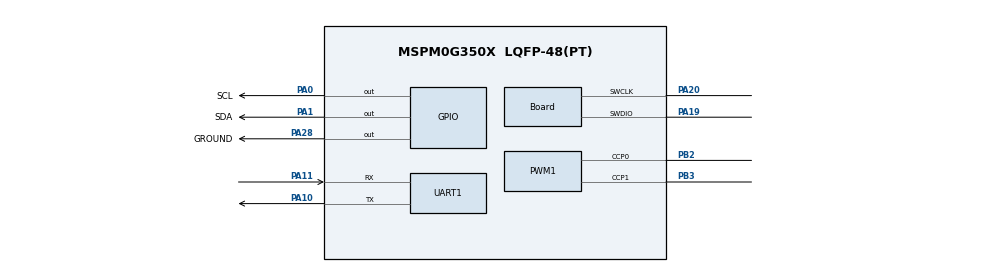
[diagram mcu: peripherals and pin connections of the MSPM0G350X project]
/**
 * These arguments were used when this file was generated. They will be automatically applied on subsequent loads
 * via the GUI or CLI. Run CLI with '--help' for additional information on how to override these arguments.
 * @cliArgs --device "MSPM0G350X" --package "LQFP-48(PT)" --part "Default" --product "mspm0_sdk@2.01.00.03"
 * @versions {"tool":"1.20.0+3587"}
 */

/**
 * Import the modules used in this configuration.
 */
const GPIO          = scripting.addModule("/ti/driverlib/GPIO", {}, false);
const GPIO1         = GPIO.addInstance();
const GPIO2         = GPIO.addInstance();
const GPIO3         = GPIO.addInstance();
const GPIO4         = GPIO.addInstance();
const GPIO5         = GPIO.addInstance();
const PWM           = scripting.addModule("/ti/driverlib/PWM", {}, false);
const PWM1          = PWM.addInstance();
const SYSCTL        = scripting.addModule("/ti/driverlib/SYSCTL");
const SYSTICK       = scripting.addModule("/ti/driverlib/SYSTICK");
const TIMER         = scripting.addModule("/ti/driverlib/TIMER", {}, false);
const TIMER1        = TIMER.addInstance();
const UART          = scripting.addModule("/ti/driverlib/UART", {}, false);
const UART1         = UART.addInstance();
const ProjectConfig = scripting.addModule("/ti/project_config/ProjectConfig");

/**
 * Write custom configuration values to the imported modules.
 */
const gate7  = system.clockTree["MFCLKGATE"];
gate7.enable = true;

GPIO1.port                           = "PORTA";
GPIO1.$name                          = "MPU6050";
GPIO1.associatedPins.create(2);
GPIO1.associatedPins[0].$name        = "SCL";
GPIO1.associatedPins[0].initialValue = "SET";
GPIO1.associatedPins[0].assignedPin  = "0";
GPIO1.associatedPins[0].ioStructure  = "OD";
GPIO1.associatedPins[0].pin.$assign  = "PA0";
GPIO1.associatedPins[1].$name        = "SDA";
GPIO1.associatedPins[1].initialValue = "SET";
GPIO1.associatedPins[1].assignedPin  = "1";
GPIO1.associatedPins[1].ioStructure  = "OD";
GPIO1.associatedPins[1].pin.$assign  = "PA1";

const Board                       = scripting.addModule("/ti/driverlib/Board", {}, false);
Board.peripheral.$assign          = "DEBUGSS";
Board.peripheral.swclkPin.$assign = "PA20";
Board.peripheral.swdioPin.$assign = "PA19";

GPIO2.$name                         = "GPIO_GRP_A";
GPIO2.port                          = "PORTA";
GPIO2.associatedPins.create(2);
GPIO2.associatedPins[0].$name       = "PIN_Ain1";
GPIO2.associatedPins[0].assignedPin = "8";
GPIO2.associatedPins[1].$name       = "PIN_Ain2";
GPIO2.associatedPins[1].assignedPin = "9";

GPIO3.$name                         = "GPIO_GRP_B";
GPIO3.port                          = "PORTB";
GPIO3.associatedPins.create(2);
GPIO3.associatedPins[0].$name       = "PIN_Bin1";
GPIO3.associatedPins[0].assignedPin = "6";
GPIO3.associatedPins[1].$name       = "PIN_Bin2";
GPIO3.associatedPins[1].assignedPin = "7";

GPIO4.$name                              = "GPIO_GRP_0";
GPIO4.associatedPins.create(4);
GPIO4.associatedPins[0].$name            = "PIN_Buzzer";
GPIO4.associatedPins[0].assignedPin      = "18";
GPIO4.associatedPins[1].$name            = "PIN_KEY1";
GPIO4.associatedPins[1].direction        = "INPUT";
GPIO4.associatedPins[1].assignedPin      = "12";
GPIO4.associatedPins[1].internalResistor = "PULL_UP";
GPIO4.associatedPins[2].$name            = "PIN_KEY2";
GPIO4.associatedPins[2].direction        = "INPUT";
GPIO4.associatedPins[2].internalResistor = "PULL_UP";
GPIO4.associatedPins[2].assignedPort     = "PORTB";
GPIO4.associatedPins[2].assignedPin      = "18";
GPIO4.associatedPins[3].$name            = "GROUND";
GPIO4.associatedPins[3].assignedPin      = "28";
GPIO4.associatedPins[3].internalResistor = "PULL_UP";
GPIO4.associatedPins[3].pin.$assign      = "PA28";

GPIO5.$name                              = "GPIO_GRP_Detect";
GPIO5.associatedPins.create(4);
GPIO5.associatedPins[0].$name            = "PIN_X1";
GPIO5.associatedPins[0].direction        = "INPUT";
GPIO5.associatedPins[0].assignedPort     = "PORTA";
GPIO5.associatedPins[0].assignedPin      = "23";
GPIO5.associatedPins[0].internalResistor = "PULL_DOWN";
GPIO5.associatedPins[1].$name            = "PIN_X2";
GPIO5.associatedPins[1].direction        = "INPUT";
GPIO5.associatedPins[1].internalResistor = "PULL_DOWN";
GPIO5.associatedPins[1].assignedPort     = "PORTA";
GPIO5.associatedPins[1].assignedPin      = "24";
GPIO5.associatedPins[2].$name            = "PIN_X3";
GPIO5.associatedPins[2].direction        = "INPUT";
GPIO5.associatedPins[2].assignedPort     = "PORTB";
GPIO5.associatedPins[2].assignedPin      = "24";
GPIO5.associatedPins[3].$name            = "PIN_X4";
GPIO5.associatedPins[3].direction        = "INPUT";
GPIO5.associatedPins[3].assignedPin      = "20";
GPIO5.associatedPins[3].assignedPort     = "PORTB";

PWM1.$name                              = "PWM_AB";
PWM1.clockPrescale                      = 256;
PWM1.timerCount                         = 2000;
PWM1.peripheral.$assign                 = "TIMA1";
PWM1.peripheral.ccp0Pin.$assign         = "PB2";
PWM1.peripheral.ccp1Pin.$assign         = "PB3";
PWM1.PWM_CHANNEL_0.$name                = "ti_driverlib_pwm_PWMTimerCC0";
PWM1.PWM_CHANNEL_0.dutyCycle            = 75;
PWM1.PWM_CHANNEL_1.$name                = "ti_driverlib_pwm_PWMTimerCC1";
PWM1.PWM_CHANNEL_1.dutyCycle            = 75;
PWM1.ccp0PinConfig.direction            = scripting.forceWrite("OUTPUT");
PWM1.ccp0PinConfig.hideOutputInversion  = scripting.forceWrite(false);
PWM1.ccp0PinConfig.onlyInternalResistor = scripting.forceWrite(false);
PWM1.ccp0PinConfig.passedPeripheralType = scripting.forceWrite("Digital");
PWM1.ccp0PinConfig.$name                = "ti_driverlib_gpio_GPIOPinGeneric2";
PWM1.ccp1PinConfig.direction            = scripting.forceWrite("OUTPUT");
PWM1.ccp1PinConfig.hideOutputInversion  = scripting.forceWrite(false);
PWM1.ccp1PinConfig.onlyInternalResistor = scripting.forceWrite(false);
PWM1.ccp1PinConfig.passedPeripheralType = scripting.forceWrite("Digital");
PWM1.ccp1PinConfig.$name                = "ti_driverlib_gpio_GPIOPinGeneric3";

SYSCTL.clockTreeEn           = true;
SYSCTL.forceDefaultClkConfig = true;

SYSTICK.periodEnable      = true;
SYSTICK.systickEnable     = true;
SYSTICK.interruptPriority = "0";
SYSTICK.period            = 32;

TIMER1.$name            = "TIMER_10ms";
TIMER1.timerClkDiv      = 8;
TIMER1.timerClkPrescale = 80;
TIMER1.timerPeriod      = "10 ms";
TIMER1.timerMode        = "PERIODIC_UP";
TIMER1.timerStartTimer  = true;
TIMER1.interrupts       = ["ZERO"];

UART1.$name                    = "UART_0";
UART1.uartClkSrc               = "MFCLK";
UART1.enabledInterrupts        = ["RX"];
UART1.peripheral.$assign       = "UART0";
UART1.peripheral.rxPin.$assign = "PA11";
UART1.peripheral.txPin.$assign = "PA10";
UART1.txPinConfig.$name        = "ti_driverlib_gpio_GPIOPinGeneric0";
UART1.rxPinConfig.$name        = "ti_driverlib_gpio_GPIOPinGeneric1";

ProjectConfig.deviceSpin = "MSPM0G3507";
scripting.suppress("Migrating requires going through the Switch Board or Device menu in the Device View section\\.", ProjectConfig, "deviceSpin");

/**
 * Pinmux solution for unlocked pins/peripherals. This ensures that minor changes to the automatic solver in a future
 * version of the tool will not impact the pinmux you originally saw.  These lines can be completely deleted in order to
 * re-solve from scratch.
 */
GPIO2.associatedPins[0].pin.$suggestSolution = "PA8";
GPIO2.associatedPins[1].pin.$suggestSolution = "PA9";
GPIO3.associatedPins[0].pin.$suggestSolution = "PB6";
GPIO3.associatedPins[1].pin.$suggestSolution = "PB7";
GPIO4.associatedPins[0].pin.$suggestSolution = "PA18";
GPIO4.associatedPins[1].pin.$suggestSolution = "PA12";
GPIO4.associatedPins[2].pin.$suggestSolution = "PB18";
GPIO5.associatedPins[0].pin.$suggestSolution = "PA23";
GPIO5.associatedPins[1].pin.$suggestSolution = "PA24";
GPIO5.associatedPins[2].pin.$suggestSolution = "PB24";
GPIO5.associatedPins[3].pin.$suggestSolution = "PB20";
TIMER1.peripheral.$suggestSolution           = "TIMA0";
